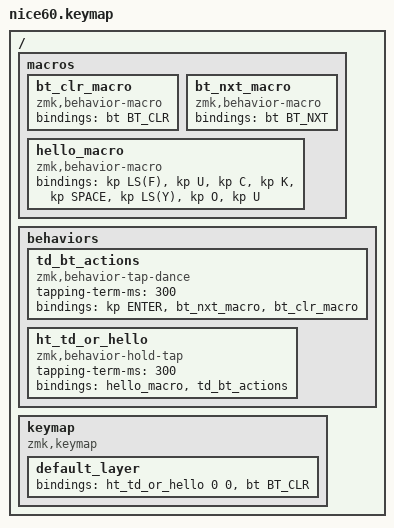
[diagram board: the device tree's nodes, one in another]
/*
 * Copyright (c) 2021 Nick Winans
 *
 * SPDX-License-Identifier: MIT
 */

#include <dt-bindings/zmk/keys.h>
#include <behaviors.dtsi>
#include <dt-bindings/zmk/bt.h>


/ {

    macros {
        bt_clr_macro: bt_clr_macro {
            compatible = "zmk,behavior-macro";
            #binding-cells = <0>;
            bindings = <&bt BT_CLR>;
        };
        bt_nxt_macro: bt_nxt_macro {
            compatible = "zmk,behavior-macro";
            #binding-cells = <0>;
            bindings = <&bt BT_NXT>;
        };
        hello_macro: hello_macro {
            compatible = "zmk,behavior-macro";
            #binding-cells = <0>;
            bindings = <&kp LS(F)>, <&kp U>, <&kp C>, <&kp K>, <&kp SPACE>, <&kp LS(Y)>, <&kp O>, <&kp U>;
        };
    };

    behaviors {
        td_bt_actions: td_bt_actions {
            compatible = "zmk,behavior-tap-dance";
            tapping-term-ms = <300>;
            #binding-cells = <0>;
            bindings = <&kp ENTER>, <&bt_nxt_macro>, <&bt_clr_macro>;
        };
        ht_td_or_hello: ht_td_or_hello {
            compatible = "zmk,behavior-hold-tap";
            tapping-term-ms = <300>; 
            #binding-cells = <2>;
            bindings = <&hello_macro>, <&td_bt_actions>;
        };
    };

    keymap {
        compatible = "zmk,keymap";

        default_layer {
            bindings = <
                &ht_td_or_hello 0 0
                &bt BT_CLR
            >;
        };
    };
};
